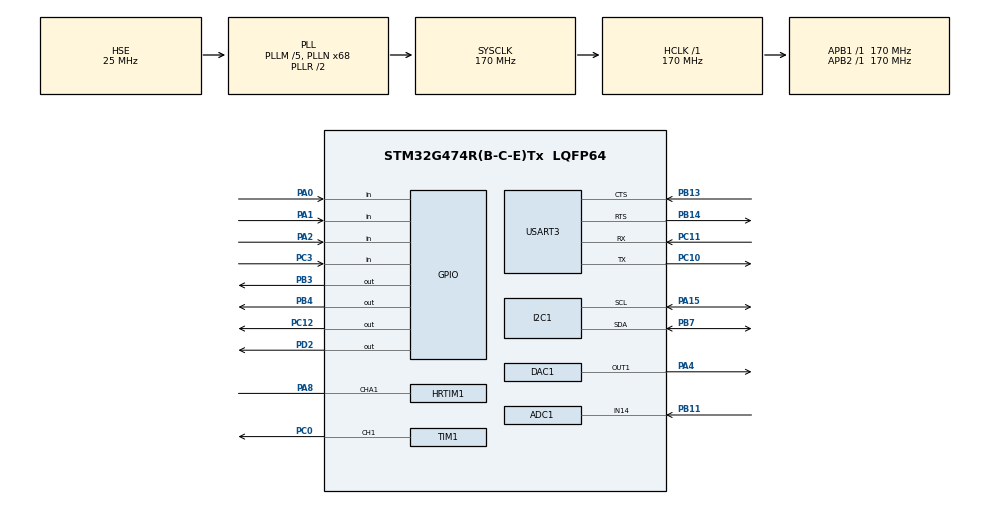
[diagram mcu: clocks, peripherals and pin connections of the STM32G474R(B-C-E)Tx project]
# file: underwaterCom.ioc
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ADC1.Channel-0\#ChannelRegularConversion=ADC_CHANNEL_14
ADC1.DMAContinuousRequests=ENABLE
ADC1.ExternalTrigConv=ADC_EXTERNALTRIG_T6_TRGO
ADC1.NbrOfConversionFlag=1
ADC1.OffsetNumber-0\#ChannelRegularConversion=ADC_OFFSET_NONE
ADC1.Rank-0\#ChannelRegularConversion=1
ADC1.SamplingTime-0\#ChannelRegularConversion=ADC_SAMPLETIME_12CYCLES_5
ADC1.master=1
Dma.ADC1.0.Direction=DMA_PERIPH_TO_MEMORY
Dma.ADC1.0.EventEnable=DISABLE
Dma.ADC1.0.Instance=DMA1_Channel1
Dma.ADC1.0.MemDataAlignment=DMA_MDATAALIGN_HALFWORD
Dma.ADC1.0.MemInc=DMA_MINC_ENABLE
Dma.ADC1.0.Mode=DMA_CIRCULAR
Dma.ADC1.0.PeriphDataAlignment=DMA_PDATAALIGN_HALFWORD
Dma.ADC1.0.PeriphInc=DMA_PINC_DISABLE
Dma.ADC1.0.Polarity=HAL_DMAMUX_REQ_GEN_RISING
Dma.ADC1.0.Priority=DMA_PRIORITY_HIGH
Dma.ADC1.0.RequestNumber=1
Dma.ADC1.0.SignalID=NONE
Dma.ADC1.0.SyncEnable=DISABLE
Dma.ADC1.0.SyncPolarity=HAL_DMAMUX_SYNC_NO_EVENT
Dma.ADC1.0.SyncRequestNumber=1
Dma.ADC1.0.SyncSignalID=NONE
Dma.Request0=ADC1
HRTIM1.CompareUnit1-Output_TA1=HRTIM_COMPAREUNIT_1
HRTIM1.CompareValue1-Output_TA1=18133
HRTIM1.NumberResetSource1-Output_TA1=1
HRTIM1.NumberSetSource1-Output_TA1=1
HRTIM1.Periode_TA=36267
HRTIM1.PrescalerRatio_TA=HRTIM_PRESCALERRATIO_MUL16
HRTIM1.ResetOutput1_Source1-Output_TA1=HRTIM_OUTPUTRESET_TIMCMP1
HRTIM1.SetOutput1_Source1-Output_TA1=HRTIM_OUTPUTSET_TIMPER
I2C1.Timing=0x40B285C2
Mcu.Family=STM32G4
Mcu.Name=STM32G474R(B-C-E)Tx
Mcu.Package=LQFP64
NVIC.DMA1_Channel1_IRQn=true\:0\:0\:false\:false\:true\:false\:true\:true
NVIC.PriorityGroup=NVIC_PRIORITYGROUP_4
PA0.Signal=GPIO_Input
PA1.Signal=GPIO_Input
PA13.Mode=Serial_Wire
PA13.Signal=SYS_JTMS-SWDIO
PA14.Mode=Serial_Wire
PA14.Signal=SYS_JTCK-SWCLK
PA15.Mode=I2C
PA15.Signal=I2C1_SCL
PA2.Signal=GPIO_Input
PA4.Signal=COMP_DAC11_group
PA8.Mode=Output_TA1
PA8.Signal=HRTIM1_CHA1
PB11.Mode=IN14-Single-Ended
PB11.Signal=ADC1_IN14
PB13.Mode=CTS_RTS
PB13.Signal=USART3_CTS
PB14.Mode=CTS_RTS
PB14.Signal=USART3_RTS
PB3.Signal=GPIO_Output
PB4.Signal=GPIO_Output
PB7.Mode=I2C
PB7.Signal=I2C1_SDA
PC0.Signal=S_TIM1_CH1
PC10.Mode=Asynchronous
PC10.Signal=USART3_TX
PC11.Mode=Asynchronous
PC11.Signal=USART3_RX
PC12.Signal=GPIO_Output
PC3.Signal=GPIO_Input
PD2.Signal=GPIO_Output
PF0-OSC_IN.Mode=HSE-External-Oscillator
PF0-OSC_IN.Signal=RCC_OSC_IN
PF1-OSC_OUT.Mode=HSE-External-Oscillator
PF1-OSC_OUT.Signal=RCC_OSC_OUT
ProjectManager.HeapSize=0x200
ProjectManager.StackSize=0x400
ProjectManager.TargetToolchain=Makefile
RCC.ADC12Freq_Value=170000000
RCC.ADC345Freq_Value=170000000
RCC.AHBFreq_Value=170000000
RCC.APB1Freq_Value=170000000
RCC.APB1TimFreq_Value=170000000
RCC.APB2Freq_Value=170000000
RCC.APB2TimFreq_Value=170000000
RCC.CortexFreq_Value=170000000
RCC.EXTERNAL_CLOCK_VALUE=12288000
RCC.HCLKFreq_Value=170000000
RCC.HSE_VALUE=25000000
RCC.HSI48_VALUE=48000000
RCC.HSI_VALUE=16000000
RCC.LSE_VALUE=32768
RCC.PLLM=RCC_PLLM_DIV5
RCC.PLLN=68
RCC.PLLSourceVirtual=RCC_PLLSOURCE_HSE
RCC.SYSCLKFreq_VALUE=170000000
RCC.SYSCLKSource=RCC_SYSCLKSOURCE_PLLCLK
RCC.USBFreq_Value=170000000
RCC.VCOOutputFreq_Value=340000000
SH.COMP_DAC11_group.0=DAC1_OUT1,DAC_OUT1
SH.S_TIM1_CH1.0=TIM1_CH1,PWM Generation1 CH1
TIM1.Channel-PWM\ Generation1\ CH1=TIM_CHANNEL_1
TIM1.PeriodNoDither=999
TIM1.Prescaler=3399
TIM6.PeriodNoDither=339
TIM6.TIM_MasterOutputTrigger=TIM_TRGO_UPDATE
USART3.VirtualMode-Asynchronous=VM_ASYNC
VP_SYS_VS_DBSignals.Mode=DisableDeadBatterySignals
VP_TIM1_VS_ClockSourceINT.Mode=Internal
VP_TIM6_VS_ClockSourceINT.Mode=Enable_Timer
board=custom

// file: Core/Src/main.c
/* USER CODE BEGIN Header */
/**
  ******************************************************************************
  * @file           : main.c
  * @brief          : Main program body
  ******************************************************************************
  * @attention
  *
  * Copyright (c) 2026 STMicroelectronics.
  * All rights reserved.
  *
  * This software is licensed under terms that can be found in the LICENSE file
  * in the root directory of this software component.
  * If no LICENSE file comes with this software, it is provided AS-IS.
  *
  ******************************************************************************
  */
/* USER CODE END Header */
#include "main.h"
#include "adc.h"
#include "dac.h"
#include "dma.h"
#include "hrtim.h"
#include "i2c.h"
#include "tim.h"
#include "usart.h"
#include "gpio.h"

/* USER CODE BEGIN Includes */
#include "maintask.hpp"

/* USER CODE END Includes */

void SystemClock_Config(void);

int main(void)
{

  /* MCU Configuration--------------------------------------------------------*/

  /* Reset of all peripherals, Initializes the Flash interface and the Systick. */
  HAL_Init();

  /* Configure the system clock */
  SystemClock_Config();

  /* Initialize all configured peripherals */
  MX_GPIO_Init();
  MX_DMA_Init();
  MX_DAC1_Init();
  MX_HRTIM1_Init();
  MX_ADC1_Init();
  MX_I2C1_Init();
  MX_TIM1_Init();
  MX_USART3_UART_Init();
  MX_TIM6_Init();
  /* USER CODE BEGIN 2 */
  UnderwaterComm_MainTask_Init();

  /* USER CODE END 2 */

  /* Infinite loop */
  while (1)
  {

    /* USER CODE BEGIN 3 */
    UnderwaterComm_MainTask_Run();
  }
  /* USER CODE END 3 */
}

void SystemClock_Config(void)
{
  RCC_OscInitTypeDef RCC_OscInitStruct = {0};
  RCC_ClkInitTypeDef RCC_ClkInitStruct = {0};

  /** Configure the main internal regulator output voltage
  */
  HAL_PWREx_ControlVoltageScaling(PWR_REGULATOR_VOLTAGE_SCALE1_BOOST);

  /** Initializes the RCC Oscillators according to the specified parameters
  * in the RCC_OscInitTypeDef structure.
  */
  RCC_OscInitStruct.OscillatorType = RCC_OSCILLATORTYPE_HSE;
  RCC_OscInitStruct.HSEState = RCC_HSE_ON;
  RCC_OscInitStruct.PLL.PLLState = RCC_PLL_ON;
  RCC_OscInitStruct.PLL.PLLSource = RCC_PLLSOURCE_HSE;
  RCC_OscInitStruct.PLL.PLLM = RCC_PLLM_DIV5;
  RCC_OscInitStruct.PLL.PLLN = 68;
  RCC_OscInitStruct.PLL.PLLP = RCC_PLLP_DIV2;
  RCC_OscInitStruct.PLL.PLLQ = RCC_PLLQ_DIV2;
  RCC_OscInitStruct.PLL.PLLR = RCC_PLLR_DIV2;
  if (HAL_RCC_OscConfig(&RCC_OscInitStruct) != HAL_OK)
  {
    Error_Handler();
  }

  /** Initializes the CPU, AHB and APB buses clocks
  */
  RCC_ClkInitStruct.ClockType = RCC_CLOCKTYPE_HCLK|RCC_CLOCKTYPE_SYSCLK
                              |RCC_CLOCKTYPE_PCLK1|RCC_CLOCKTYPE_PCLK2;
  RCC_ClkInitStruct.SYSCLKSource = RCC_SYSCLKSOURCE_PLLCLK;
  RCC_ClkInitStruct.AHBCLKDivider = RCC_SYSCLK_DIV1;
  RCC_ClkInitStruct.APB1CLKDivider = RCC_HCLK_DIV1;
  RCC_ClkInitStruct.APB2CLKDivider = RCC_HCLK_DIV1;

  if (HAL_RCC_ClockConfig(&RCC_ClkInitStruct, FLASH_LATENCY_4) != HAL_OK)
  {
    Error_Handler();
  }
}

void Error_Handler(void)
{
  __disable_irq();
  while (1)
  {
  }
}
